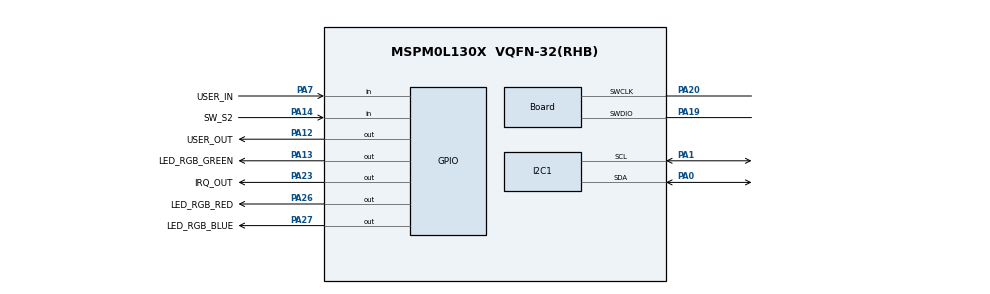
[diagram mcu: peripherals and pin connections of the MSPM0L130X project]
// @cliArgs --device "MSPM0L130X" --package "VQFN-32(RHB)" --part "Default"
// @cliArgs --board /ti/boards/LP_MSPM0L1306 --rtos nortos

/**
 * Import the modules used in this configuration.
 */
const Board  = scripting.addModule("/ti/driverlib/Board");
const GPIO   = scripting.addModule("/ti/driverlib/GPIO", {}, false);
const GPIO1  = GPIO.addInstance();
const I2C    = scripting.addModule("/ti/driverlib/I2C", {}, false);
const I2C1   = I2C.addInstance();
const SYSCTL = scripting.addModule("/ti/driverlib/SYSCTL");
const TIMER  = scripting.addModule("/ti/driverlib/TIMER", {}, false);
const TIMER1 = TIMER.addInstance();

/**
 * Write custom configuration values to the imported modules.
 */
Board.configureUnused             = true;
Board.genPeriphPinFile            = true;
Board.peripheral.$assign          = "DEBUGSS";
Board.peripheral.swclkPin.$assign = "PA20";
Board.peripheral.swdioPin.$assign = "PA19";
Board.genFileMod.$name            = "ti_driverlib_BoardPins0";

GPIO1.$name                              = "GPIO_A";
GPIO1.associatedPins.create(8);
GPIO1.associatedPins[0].assignedPin      = "13";
GPIO1.associatedPins[0].assignedPort     = "PORTA";
GPIO1.associatedPins[0].$name            = "LED_RGB_GREEN";
GPIO1.associatedPins[0].pin.$assign      = "PA13";
GPIO1.associatedPins[1].assignedPin      = "26";
GPIO1.associatedPins[1].assignedPort     = "PORTA";
GPIO1.associatedPins[1].$name            = "LED_RGB_RED";
GPIO1.associatedPins[1].pin.$assign      = "PA26";
GPIO1.associatedPins[2].assignedPin      = "27";
GPIO1.associatedPins[2].assignedPort     = "PORTA";
GPIO1.associatedPins[2].$name            = "LED_RGB_BLUE";
GPIO1.associatedPins[2].pin.$assign      = "PA27";
GPIO1.associatedPins[3].initialValue     = "SET";
GPIO1.associatedPins[3].subOutputPolicy  = "TOGGLE";
GPIO1.associatedPins[3].subChanID        = 1;
GPIO1.associatedPins[3].assignedPin      = "23";
GPIO1.associatedPins[3].internalResistor = "PULL_UP";
GPIO1.associatedPins[3].hiZ              = "ENABLE";
GPIO1.associatedPins[3].assignedPort     = "PORTA";
GPIO1.associatedPins[3].$name            = "IRQ_OUT";
GPIO1.associatedPins[3].pin.$assign      = "PA23";
GPIO1.associatedPins[4].ioStructure      = "SD";
GPIO1.associatedPins[4].assignedPort     = "PORTA";
GPIO1.associatedPins[4].assignedPin      = "12";
GPIO1.associatedPins[4].$name            = "USER_OUT";
GPIO1.associatedPins[4].pin.$assign      = "PA12";
GPIO1.associatedPins[5].direction        = "INPUT";
GPIO1.associatedPins[5].ioStructure      = "SD";
GPIO1.associatedPins[5].internalResistor = "PULL_DOWN";
GPIO1.associatedPins[5].$name            = "USER_IN";
GPIO1.associatedPins[5].assignedPort     = "PORTA";
GPIO1.associatedPins[5].assignedPin      = "7";
GPIO1.associatedPins[5].inputFilter      = "8_CYCLES";
GPIO1.associatedPins[5].pin.$assign      = "PA7";
GPIO1.associatedPins[6].$name            = "SW_S1";
GPIO1.associatedPins[6].direction        = "INPUT";
GPIO1.associatedPins[6].interruptEn      = true;
GPIO1.associatedPins[6].polarity         = "RISE_FALL";
GPIO1.associatedPins[6].inputFilter      = "3_CYCLES";
GPIO1.associatedPins[6].assignedPin      = "18";
GPIO1.associatedPins[7].$name            = "SW_S2";
GPIO1.associatedPins[7].direction        = "INPUT";
GPIO1.associatedPins[7].internalResistor = "PULL_UP";
GPIO1.associatedPins[7].interruptEn      = true;
GPIO1.associatedPins[7].polarity         = "RISE_FALL";
GPIO1.associatedPins[7].assignedPin      = "14";
GPIO1.associatedPins[7].inputFilter      = "3_CYCLES";
GPIO1.associatedPins[7].pin.$assign      = "PA14";

I2C1.basicTargetAddress                = 0x48;
I2C1.$name                             = "I2C_TARGET";
I2C1.basicEnableTarget                 = true;
I2C1.intTarget                         = ["RXFIFO_TRIGGER","START","STOP"];
I2C1.advTargetClkStretch               = false;
I2C1.advTargetTXFIFOTRIG               = "BYTES_1";
I2C1.advAnalogGlitchFilter             = "DISABLED";
I2C1.peripheral.$assign                = "I2C0";
I2C1.peripheral.sdaPin.$assign         = "PA0";
I2C1.peripheral.sclPin.$assign         = "PA1";

TIMER1.timerClkSrc = "LFCLK";
TIMER1.$name       = "TIMG_DELAY_BLOCKING";
TIMER1.timerPeriod = "1 ms";
TIMER1.interrupts  = ["ZERO"];
